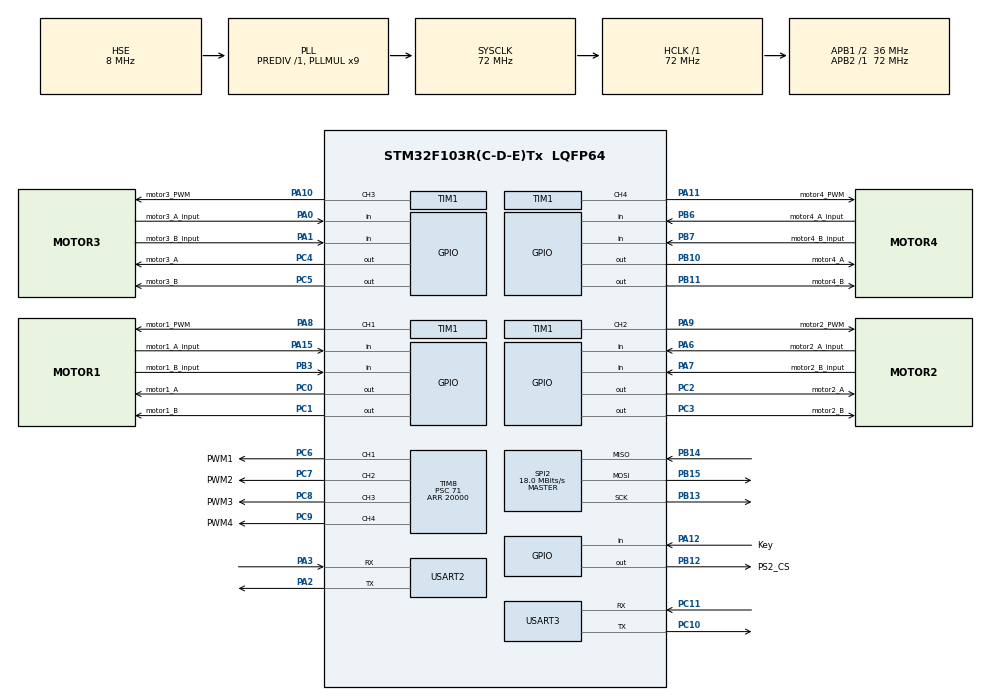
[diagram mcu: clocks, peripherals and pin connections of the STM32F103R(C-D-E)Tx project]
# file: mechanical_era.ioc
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Mcu.Family=STM32F1
Mcu.Name=STM32F103R(C-D-E)Tx
Mcu.Package=LQFP64
NVIC.PriorityGroup=NVIC_PRIORITYGROUP_4
PA0-WKUP.GPIO_Label=motor3_A_input
PA0-WKUP.Signal=GPIO_Input
PA1.GPIO_Label=motor3_B_input
PA1.Signal=GPIO_Input
PA10.GPIO_Label=motor3_PWM
PA10.Signal=S_TIM1_CH3
PA11.GPIO_Label=motor4_PWM
PA11.Signal=S_TIM1_CH4
PA12.GPIO_Label=Key
PA12.GPIO_PuPd=GPIO_PULLUP
PA12.Signal=GPIO_Input
PA13.Mode=Serial_Wire
PA13.Signal=SYS_JTMS-SWDIO
PA14.Mode=Serial_Wire
PA14.Signal=SYS_JTCK-SWCLK
PA15.GPIO_Label=motor1_A_input
PA15.Signal=GPIO_Input
PA2.Mode=Asynchronous
PA2.Signal=USART2_TX
PA3.Mode=Asynchronous
PA3.Signal=USART2_RX
PA6.GPIO_Label=motor2_A_input
PA6.Signal=GPIO_Input
PA7.GPIO_Label=motor2_B_input
PA7.Signal=GPIO_Input
PA8.GPIO_Label=motor1_PWM
PA8.Signal=S_TIM1_CH1
PA9.GPIO_Label=motor2_PWM
PA9.Signal=S_TIM1_CH2
PB10.GPIO_Label=motor4_A
PB10.Signal=GPIO_Output
PB11.GPIO_Label=motor4_B
PB11.Signal=GPIO_Output
PB12.GPIO_Label=PS2_CS
PB12.GPIO_OutputLevel=GPIO_PIN_SET
PB12.Signal=GPIO_Output
PB13.Mode=Full_Duplex_Master
PB13.Signal=SPI2_SCK
PB14.GPIO_PuPd=GPIO_PULLUP
PB14.Mode=Full_Duplex_Master
PB14.Signal=SPI2_MISO
PB15.Mode=Full_Duplex_Master
PB15.Signal=SPI2_MOSI
PB3.GPIO_Label=motor1_B_input
PB3.Signal=GPIO_Input
PB6.GPIO_Label=motor4_A_input
PB6.Signal=GPIO_Input
PB7.GPIO_Label=motor4_B_input
PB7.Signal=GPIO_Input
PC0.GPIO_Label=motor1_A
PC0.Signal=GPIO_Output
PC1.GPIO_Label=motor1_B
PC1.Signal=GPIO_Output
PC10.Mode=Asynchronous
PC10.Signal=USART3_TX
PC11.Mode=Asynchronous
PC11.Signal=USART3_RX
PC2.GPIO_Label=motor2_A
PC2.Signal=GPIO_Output
PC3.GPIO_Label=motor2_B
PC3.Signal=GPIO_Output
PC4.GPIO_Label=motor3_A
PC4.Signal=GPIO_Output
PC5.GPIO_Label=motor3_B
PC5.Signal=GPIO_Output
PC6.GPIO_Label=PWM1
PC6.Signal=S_TIM8_CH1
PC7.GPIO_Label=PWM2
PC7.Signal=S_TIM8_CH2
PC8.GPIO_Label=PWM3
PC8.Signal=S_TIM8_CH3
PC9.GPIO_Label=PWM4
PC9.Signal=S_TIM8_CH4
PD0-OSC_IN.Mode=HSE-External-Oscillator
PD0-OSC_IN.Signal=RCC_OSC_IN
PD1-OSC_OUT.Mode=HSE-External-Oscillator
PD1-OSC_OUT.Signal=RCC_OSC_OUT
ProjectManager.HeapSize=0x200
ProjectManager.StackSize=0x400
ProjectManager.TargetToolchain=CMake
RCC.AHBFreq_Value=72000000
RCC.APB1CLKDivider=RCC_HCLK_DIV2
RCC.APB1Freq_Value=36000000
RCC.APB1TimFreq_Value=72000000
RCC.APB2Freq_Value=72000000
RCC.APB2TimFreq_Value=72000000
RCC.HCLKFreq_Value=72000000
RCC.PLLMUL=RCC_PLL_MUL9
RCC.PLLSourceVirtual=RCC_PLLSOURCE_HSE
RCC.SYSCLKFreq_VALUE=72000000
RCC.SYSCLKSource=RCC_SYSCLKSOURCE_PLLCLK
RCC.USBFreq_Value=72000000
SH.S_TIM1_CH1.0=TIM1_CH1,PWM Generation1 CH1
SH.S_TIM1_CH2.0=TIM1_CH2,PWM Generation2 CH2
SH.S_TIM1_CH3.0=TIM1_CH3,PWM Generation3 CH3
SH.S_TIM1_CH4.0=TIM1_CH4,PWM Generation4 CH4
SH.S_TIM8_CH1.0=TIM8_CH1,PWM Generation1 CH1
SH.S_TIM8_CH2.0=TIM8_CH2,PWM Generation2 CH2
SH.S_TIM8_CH3.0=TIM8_CH3,PWM Generation3 CH3
SH.S_TIM8_CH4.0=TIM8_CH4,PWM Generation4 CH4
SPI2.CalculateBaudRate=18.0 MBits/s
SPI2.Direction=SPI_DIRECTION_2LINES
SPI2.Mode=SPI_MODE_MASTER
SPI2.VirtualType=VM_MASTER
TIM1.Channel-PWM\ Generation1\ CH1=TIM_CHANNEL_1
TIM1.Channel-PWM\ Generation2\ CH2=TIM_CHANNEL_2
TIM1.Channel-PWM\ Generation3\ CH3=TIM_CHANNEL_3
TIM1.Channel-PWM\ Generation4\ CH4=TIM_CHANNEL_4
TIM8.Channel-PWM\ Generation1\ CH1=TIM_CHANNEL_1
TIM8.Channel-PWM\ Generation2\ CH2=TIM_CHANNEL_2
TIM8.Channel-PWM\ Generation3\ CH3=TIM_CHANNEL_3
TIM8.Channel-PWM\ Generation4\ CH4=TIM_CHANNEL_4
TIM8.Period=20000
TIM8.Prescaler=71
USART2.VirtualMode=VM_ASYNC
USART3.VirtualMode=VM_ASYNC
VP_TIM1_VS_ClockSourceINT.Mode=Internal
VP_TIM8_VS_ClockSourceINT.Mode=Internal
board=custom

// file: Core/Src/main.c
/* USER CODE BEGIN Header */
/**
  ******************************************************************************
  * @file           : main.c
  * @brief          : 主程序
  ******************************************************************************
  * @attention
  *
  * Copyright (c) 2026 STMicroelectronics.
  * All rights reserved.
  *
  * This software is licensed under terms that can be found in the LICENSE file
  * in the root directory of this software component.
  * If no LICENSE file comes with this software, it is provided AS-IS.
  *
  ******************************************************************************
  */
/* USER CODE END Header */
#include "main.h"

/* USER CODE BEGIN Includes */
#include "app.h"

/* USER CODE END Includes */

SPI_HandleTypeDef hspi2;

TIM_HandleTypeDef htim1;
TIM_HandleTypeDef htim8;

UART_HandleTypeDef huart2;
UART_HandleTypeDef huart3;

void SystemClock_Config(void);
static void MX_GPIO_Init(void);
static void MX_SPI2_Init(void);
static void MX_TIM1_Init(void);
static void MX_TIM8_Init(void);
static void MX_USART2_UART_Init(void);
static void MX_USART3_UART_Init(void);

int main(void)
{

  /* MCU Configuration--------------------------------------------------------*/

  /* Reset of all peripherals, Initializes the Flash interface and the Systick. */
  HAL_Init();

  /* Configure the system clock */
  SystemClock_Config();

  /* Initialize all configured peripherals */
  MX_GPIO_Init();
  MX_SPI2_Init();
  MX_TIM1_Init();
  MX_TIM8_Init();
  MX_USART2_UART_Init();
  MX_USART3_UART_Init();
  /* USER CODE BEGIN 2 */
  main_task();
  /* USER CODE END 2 */

  /* Infinite loop */
  while (1)
  {

  }
}

void SystemClock_Config(void)
{
  RCC_OscInitTypeDef RCC_OscInitStruct = {0};
  RCC_ClkInitTypeDef RCC_ClkInitStruct = {0};

  /** Initializes the RCC Oscillators according to the specified parameters
  * in the RCC_OscInitTypeDef structure.
  */
  RCC_OscInitStruct.OscillatorType = RCC_OSCILLATORTYPE_HSE;
  RCC_OscInitStruct.HSEState = RCC_HSE_ON;
  RCC_OscInitStruct.HSEPredivValue = RCC_HSE_PREDIV_DIV1;
  RCC_OscInitStruct.HSIState = RCC_HSI_ON;
  RCC_OscInitStruct.PLL.PLLState = RCC_PLL_ON;
  RCC_OscInitStruct.PLL.PLLSource = RCC_PLLSOURCE_HSE;
  RCC_OscInitStruct.PLL.PLLMUL = RCC_PLL_MUL9;
  if (HAL_RCC_OscConfig(&RCC_OscInitStruct) != HAL_OK)
  {
    Error_Handler();
  }

  /** Initializes the CPU, AHB and APB buses clocks
  */
  RCC_ClkInitStruct.ClockType = RCC_CLOCKTYPE_HCLK|RCC_CLOCKTYPE_SYSCLK
                              |RCC_CLOCKTYPE_PCLK1|RCC_CLOCKTYPE_PCLK2;
  RCC_ClkInitStruct.SYSCLKSource = RCC_SYSCLKSOURCE_PLLCLK;
  RCC_ClkInitStruct.AHBCLKDivider = RCC_SYSCLK_DIV1;
  RCC_ClkInitStruct.APB1CLKDivider = RCC_HCLK_DIV2;
  RCC_ClkInitStruct.APB2CLKDivider = RCC_HCLK_DIV1;

  if (HAL_RCC_ClockConfig(&RCC_ClkInitStruct, FLASH_LATENCY_2) != HAL_OK)
  {
    Error_Handler();
  }
}

static void MX_SPI2_Init(void)
{

  /* SPI2 parameter configuration*/
  hspi2.Instance = SPI2;
  hspi2.Init.Mode = SPI_MODE_MASTER;
  hspi2.Init.Direction = SPI_DIRECTION_2LINES;
  hspi2.Init.DataSize = SPI_DATASIZE_8BIT;
  hspi2.Init.CLKPolarity = SPI_POLARITY_LOW;
  hspi2.Init.CLKPhase = SPI_PHASE_1EDGE;
  hspi2.Init.NSS = SPI_NSS_SOFT;
  hspi2.Init.BaudRatePrescaler = SPI_BAUDRATEPRESCALER_2;
  hspi2.Init.FirstBit = SPI_FIRSTBIT_MSB;
  hspi2.Init.TIMode = SPI_TIMODE_DISABLE;
  hspi2.Init.CRCCalculation = SPI_CRCCALCULATION_DISABLE;
  hspi2.Init.CRCPolynomial = 10;
  if (HAL_SPI_Init(&hspi2) != HAL_OK)
  {
    Error_Handler();
  }

}

static void MX_TIM1_Init(void)
{

  TIM_ClockConfigTypeDef sClockSourceConfig = {0};
  TIM_MasterConfigTypeDef sMasterConfig = {0};
  TIM_OC_InitTypeDef sConfigOC = {0};
  TIM_BreakDeadTimeConfigTypeDef sBreakDeadTimeConfig = {0};

  htim1.Instance = TIM1;
  htim1.Init.Prescaler = 0;
  htim1.Init.CounterMode = TIM_COUNTERMODE_UP;
  htim1.Init.Period = 65535;
  htim1.Init.ClockDivision = TIM_CLOCKDIVISION_DIV1;
  htim1.Init.RepetitionCounter = 0;
  htim1.Init.AutoReloadPreload = TIM_AUTORELOAD_PRELOAD_DISABLE;
  if (HAL_TIM_Base_Init(&htim1) != HAL_OK)
  {
    Error_Handler();
  }
  sClockSourceConfig.ClockSource = TIM_CLOCKSOURCE_INTERNAL;
  if (HAL_TIM_ConfigClockSource(&htim1, &sClockSourceConfig) != HAL_OK)
  {
    Error_Handler();
  }
  if (HAL_TIM_PWM_Init(&htim1) != HAL_OK)
  {
    Error_Handler();
  }
  sMasterConfig.MasterOutputTrigger = TIM_TRGO_RESET;
  sMasterConfig.MasterSlaveMode = TIM_MASTERSLAVEMODE_DISABLE;
  if (HAL_TIMEx_MasterConfigSynchronization(&htim1, &sMasterConfig) != HAL_OK)
  {
    Error_Handler();
  }
  sConfigOC.OCMode = TIM_OCMODE_PWM1;
  sConfigOC.Pulse = 0;
  sConfigOC.OCPolarity = TIM_OCPOLARITY_HIGH;
  sConfigOC.OCNPolarity = TIM_OCNPOLARITY_HIGH;
  sConfigOC.OCFastMode = TIM_OCFAST_DISABLE;
  sConfigOC.OCIdleState = TIM_OCIDLESTATE_RESET;
  sConfigOC.OCNIdleState = TIM_OCNIDLESTATE_RESET;
  if (HAL_TIM_PWM_ConfigChannel(&htim1, &sConfigOC, TIM_CHANNEL_1) != HAL_OK)
  {
    Error_Handler();
  }
  if (HAL_TIM_PWM_ConfigChannel(&htim1, &sConfigOC, TIM_CHANNEL_2) != HAL_OK)
  {
    Error_Handler();
  }
  if (HAL_TIM_PWM_ConfigChannel(&htim1, &sConfigOC, TIM_CHANNEL_3) != HAL_OK)
  {
    Error_Handler();
  }
  if (HAL_TIM_PWM_ConfigChannel(&htim1, &sConfigOC, TIM_CHANNEL_4) != HAL_OK)
  {
    Error_Handler();
  }
  sBreakDeadTimeConfig.OffStateRunMode = TIM_OSSR_DISABLE;
  sBreakDeadTimeConfig.OffStateIDLEMode = TIM_OSSI_DISABLE;
  sBreakDeadTimeConfig.LockLevel = TIM_LOCKLEVEL_OFF;
  sBreakDeadTimeConfig.DeadTime = 0;
  sBreakDeadTimeConfig.BreakState = TIM_BREAK_DISABLE;
  sBreakDeadTimeConfig.BreakPolarity = TIM_BREAKPOLARITY_HIGH;
  sBreakDeadTimeConfig.AutomaticOutput = TIM_AUTOMATICOUTPUT_DISABLE;
  if (HAL_TIMEx_ConfigBreakDeadTime(&htim1, &sBreakDeadTimeConfig) != HAL_OK)
  {
    Error_Handler();
  }
  HAL_TIM_MspPostInit(&htim1);

}

static void MX_TIM8_Init(void)
{

  TIM_ClockConfigTypeDef sClockSourceConfig = {0};
  TIM_MasterConfigTypeDef sMasterConfig = {0};
  TIM_OC_InitTypeDef sConfigOC = {0};
  TIM_BreakDeadTimeConfigTypeDef sBreakDeadTimeConfig = {0};

  htim8.Instance = TIM8;
  htim8.Init.Prescaler = 71;
  htim8.Init.CounterMode = TIM_COUNTERMODE_UP;
  htim8.Init.Period = 20000;
  htim8.Init.ClockDivision = TIM_CLOCKDIVISION_DIV1;
  htim8.Init.RepetitionCounter = 0;
  htim8.Init.AutoReloadPreload = TIM_AUTORELOAD_PRELOAD_DISABLE;
  if (HAL_TIM_Base_Init(&htim8) != HAL_OK)
  {
    Error_Handler();
  }
  sClockSourceConfig.ClockSource = TIM_CLOCKSOURCE_INTERNAL;
  if (HAL_TIM_ConfigClockSource(&htim8, &sClockSourceConfig) != HAL_OK)
  {
    Error_Handler();
  }
  if (HAL_TIM_PWM_Init(&htim8) != HAL_OK)
  {
    Error_Handler();
  }
  sMasterConfig.MasterOutputTrigger = TIM_TRGO_RESET;
  sMasterConfig.MasterSlaveMode = TIM_MASTERSLAVEMODE_DISABLE;
  if (HAL_TIMEx_MasterConfigSynchronization(&htim8, &sMasterConfig) != HAL_OK)
  {
    Error_Handler();
  }
  sConfigOC.OCMode = TIM_OCMODE_PWM1;
  sConfigOC.Pulse = 0;
  sConfigOC.OCPolarity = TIM_OCPOLARITY_HIGH;
  sConfigOC.OCNPolarity = TIM_OCNPOLARITY_HIGH;
  sConfigOC.OCFastMode = TIM_OCFAST_DISABLE;
  sConfigOC.OCIdleState = TIM_OCIDLESTATE_RESET;
  sConfigOC.OCNIdleState = TIM_OCNIDLESTATE_RESET;
  if (HAL_TIM_PWM_ConfigChannel(&htim8, &sConfigOC, TIM_CHANNEL_1) != HAL_OK)
  {
    Error_Handler();
  }
  if (HAL_TIM_PWM_ConfigChannel(&htim8, &sConfigOC, TIM_CHANNEL_2) != HAL_OK)
  {
    Error_Handler();
  }
  if (HAL_TIM_PWM_ConfigChannel(&htim8, &sConfigOC, TIM_CHANNEL_3) != HAL_OK)
  {
    Error_Handler();
  }
  if (HAL_TIM_PWM_ConfigChannel(&htim8, &sConfigOC, TIM_CHANNEL_4) != HAL_OK)
  {
    Error_Handler();
  }
  sBreakDeadTimeConfig.OffStateRunMode = TIM_OSSR_DISABLE;
  sBreakDeadTimeConfig.OffStateIDLEMode = TIM_OSSI_DISABLE;
  sBreakDeadTimeConfig.LockLevel = TIM_LOCKLEVEL_OFF;
  sBreakDeadTimeConfig.DeadTime = 0;
  sBreakDeadTimeConfig.BreakState = TIM_BREAK_DISABLE;
  sBreakDeadTimeConfig.BreakPolarity = TIM_BREAKPOLARITY_HIGH;
  sBreakDeadTimeConfig.AutomaticOutput = TIM_AUTOMATICOUTPUT_DISABLE;
  if (HAL_TIMEx_ConfigBreakDeadTime(&htim8, &sBreakDeadTimeConfig) != HAL_OK)
  {
    Error_Handler();
  }
  HAL_TIM_MspPostInit(&htim8);

}

static void MX_USART2_UART_Init(void)
{

  huart2.Instance = USART2;
  huart2.Init.BaudRate = 115200;
  huart2.Init.WordLength = UART_WORDLENGTH_8B;
  huart2.Init.StopBits = UART_STOPBITS_1;
  huart2.Init.Parity = UART_PARITY_NONE;
  huart2.Init.Mode = UART_MODE_TX_RX;
  huart2.Init.HwFlowCtl = UART_HWCONTROL_NONE;
  huart2.Init.OverSampling = UART_OVERSAMPLING_16;
  if (HAL_UART_Init(&huart2) != HAL_OK)
  {
    Error_Handler();
  }

}

static void MX_USART3_UART_Init(void)
{

  huart3.Instance = USART3;
  huart3.Init.BaudRate = 115200;
  huart3.Init.WordLength = UART_WORDLENGTH_8B;
  huart3.Init.StopBits = UART_STOPBITS_1;
  huart3.Init.Parity = UART_PARITY_NONE;
  huart3.Init.Mode = UART_MODE_TX_RX;
  huart3.Init.HwFlowCtl = UART_HWCONTROL_NONE;
  huart3.Init.OverSampling = UART_OVERSAMPLING_16;
  if (HAL_UART_Init(&huart3) != HAL_OK)
  {
    Error_Handler();
  }

}

static void MX_GPIO_Init(void)
{
  GPIO_InitTypeDef GPIO_InitStruct = {0};

  /* GPIO Ports Clock Enable */
  __HAL_RCC_GPIOD_CLK_ENABLE();
  __HAL_RCC_GPIOC_CLK_ENABLE();
  __HAL_RCC_GPIOA_CLK_ENABLE();
  __HAL_RCC_GPIOB_CLK_ENABLE();

  /*Configure GPIO pin Output Level */
  HAL_GPIO_WritePin(GPIOC, motor1_A_Pin|motor1_B_Pin|motor2_A_Pin|motor2_B_Pin
                          |motor3_A_Pin|motor3_B_Pin, GPIO_PIN_RESET);

  /*Configure GPIO pin Output Level */
  HAL_GPIO_WritePin(GPIOB, motor4_A_Pin|motor4_B_Pin, GPIO_PIN_RESET);
  HAL_GPIO_WritePin(PS2_CS_GPIO_Port, PS2_CS_Pin, GPIO_PIN_SET);

  /*Configure GPIO pins : motor1_A_Pin motor1_B_Pin motor2_A_Pin motor2_B_Pin
                           motor3_A_Pin motor3_B_Pin */
  GPIO_InitStruct.Pin = motor1_A_Pin|motor1_B_Pin|motor2_A_Pin|motor2_B_Pin
                          |motor3_A_Pin|motor3_B_Pin;
  GPIO_InitStruct.Mode = GPIO_MODE_OUTPUT_PP;
  GPIO_InitStruct.Pull = GPIO_NOPULL;
  GPIO_InitStruct.Speed = GPIO_SPEED_FREQ_LOW;
  HAL_GPIO_Init(GPIOC, &GPIO_InitStruct);

  /*Configure GPIO pins : motor3_A_input_Pin motor3_B_input_Pin motor2_A_input_Pin motor2_B_input_Pin
                           motor1_A_input_Pin */
  GPIO_InitStruct.Pin = motor3_A_input_Pin|motor3_B_input_Pin|motor2_A_input_Pin|motor2_B_input_Pin
                          |motor1_A_input_Pin;
  GPIO_InitStruct.Mode = GPIO_MODE_INPUT;
  GPIO_InitStruct.Pull = GPIO_NOPULL;
  HAL_GPIO_Init(GPIOA, &GPIO_InitStruct);

  /*Configure GPIO pins : motor4_A_Pin motor4_B_Pin PS2_CS_Pin */
  GPIO_InitStruct.Pin = motor4_A_Pin|motor4_B_Pin|PS2_CS_Pin;
  GPIO_InitStruct.Mode = GPIO_MODE_OUTPUT_PP;
  GPIO_InitStruct.Pull = GPIO_NOPULL;
  GPIO_InitStruct.Speed = GPIO_SPEED_FREQ_LOW;
  HAL_GPIO_Init(GPIOB, &GPIO_InitStruct);

  /*Configure GPIO pin : Key_Pin */
  GPIO_InitStruct.Pin = Key_Pin;
  GPIO_InitStruct.Mode = GPIO_MODE_INPUT;
  GPIO_InitStruct.Pull = GPIO_PULLUP;
  HAL_GPIO_Init(Key_GPIO_Port, &GPIO_InitStruct);

  /*Configure GPIO pins : motor1_B_input_Pin motor4_A_input_Pin motor4_B_input_Pin */
  GPIO_InitStruct.Pin = motor1_B_input_Pin|motor4_A_input_Pin|motor4_B_input_Pin;
  GPIO_InitStruct.Mode = GPIO_MODE_INPUT;
  GPIO_InitStruct.Pull = GPIO_NOPULL;
  HAL_GPIO_Init(GPIOB, &GPIO_InitStruct);

  /* USER CODE BEGIN MX_GPIO_Init_2 */

  /* 低电平有效的停止按键必须具有确定的空闲电平。 */
  GPIO_InitStruct.Pin = Key_Pin;
  GPIO_InitStruct.Mode = GPIO_MODE_INPUT;
  GPIO_InitStruct.Pull = GPIO_PULLUP;
  HAL_GPIO_Init(Key_GPIO_Port, &GPIO_InitStruct);

  /* USER CODE END MX_GPIO_Init_2 */
}

void Error_Handler(void)
{
  /* USER CODE BEGIN Error_Handler_Debug */
  /* 用户可在此添加代码，报告 HAL 返回的错误状态 */
  __disable_irq();
  while (1)
  {
  }
  /* USER CODE END Error_Handler_Debug */
}
#ifdef USE_FULL_ASSERT
/**
  * @brief  Reports the name of the source file and the source line number
  *         where the assert_param error has occurred.
  * @param  file: pointer to the source file name
  * @param  line: assert_param error line source number
  * @retval None
  */
void assert_failed(uint8_t *file, uint32_t line)
{
  /* USER CODE BEGIN 6 */
  /* 用户可在此添加代码，报告文件名称和行号，
     例如：printf("Wrong parameters value: file %s on line %d\r\n", file, line) */
  /* USER CODE END 6 */
}
#endif /* USE_FULL_ASSERT */
